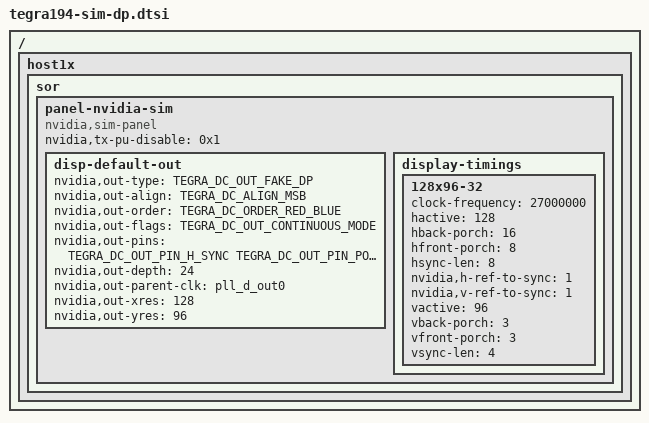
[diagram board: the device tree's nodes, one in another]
/*
 * Copyright (c) 2016, NVIDIA CORPORATION.  All rights reserved.
 *
 * This program is free software; you can redistribute it and/or modify
 * it under the terms of the GNU General Public License as published by
 * the Free Software Foundation; version 2 of the License.
 *
 * This program is distributed in the hope that it will be useful, but WITHOUT
 * ANY WARRANTY; without even the implied warranty of MERCHANTABILITY or
 * FITNESS FOR A PARTICULAR PURPOSE.  See the GNU General Public License for
 * more details.
 *
 */


/ {
	host1x {
		sor {
			panel-nvidia-sim {
				compatible = "nvidia,sim-panel";
				nvidia,tx-pu-disable = <0x1>;

				disp-default-out {
					nvidia,out-type = <TEGRA_DC_OUT_FAKE_DP>;
					nvidia,out-align = <TEGRA_DC_ALIGN_MSB>;
					nvidia,out-order = <TEGRA_DC_ORDER_RED_BLUE>;
					nvidia,out-flags = <TEGRA_DC_OUT_CONTINUOUS_MODE>;
					nvidia,out-pins = <TEGRA_DC_OUT_PIN_H_SYNC TEGRA_DC_OUT_PIN_POL_LOW
							   TEGRA_DC_OUT_PIN_V_SYNC TEGRA_DC_OUT_PIN_POL_LOW
							   TEGRA_DC_OUT_PIN_PIXEL_CLOCK TEGRA_DC_OUT_PIN_POL_LOW
							   TEGRA_DC_OUT_PIN_DATA_ENABLE TEGRA_DC_OUT_PIN_POL_HIGH>;
					nvidia,out-depth = <24>;
					nvidia,out-parent-clk = "pll_d_out0";
					nvidia,out-xres = <128>;
					nvidia,out-yres = <96>;
				};

				display-timings {
					128x96-32 {
						clock-frequency = <27000000>;
						hactive = <128>;
						hback-porch = <16>;
						hfront-porch = <8>;
						hsync-len = <8>;
						nvidia,h-ref-to-sync = <1>;
						nvidia,v-ref-to-sync = <1>;
						vactive = <96>;
						vback-porch = <3>;
						vfront-porch = <3>;
						vsync-len = <4>;
					};
				};
			}; // panel-nvidia-sim

		}; //sor
	}; // host1x
};
